# STC32G144K246 register map
Vendor: STC; File version: 2.0
Registers are 8-bit, read-write, no defined reset value unless marked. A register's access mark holds for its fields unless they carry their own. Offsets are from the block's base; [hi:lo] are bit positions; {n}, {i} and the like mark numbered series; 'fields as' and 'values as' point back to an identical list.

## PWMD — 高级 PWM D：使能、状态、计数、周期和输出
Base 0x007EF8B5
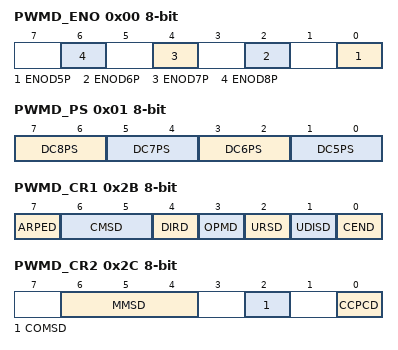
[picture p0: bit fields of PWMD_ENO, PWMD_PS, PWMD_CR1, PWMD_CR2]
0x00 PWMD_ENO — PWMD输出使能控制
  [2n-10] ENOD{n}P (n=5..8) — 尚未自动匹配到此字段的独立说明；请查看下方章节说明。
0x01 PWMD_PS — PWMD输出脚选择寄存器
  [7:6] DC8PS — 高级PWM 通道8 输出脚选择位
    0=P2.7; 1=P8.7; 2=P5.3; 3=PB.7
  [5:4] DC7PS — 高级PWMD 通道7 输出脚选择位
    0=P2.6; 1=P8.5; 2=P5.2; 3=PB.6
  [3:2] DC6PS — 高级PWMD 通道6 输出脚选择位
    0=P2.5; 1=P8.3; 2=P5.1; 3=PB.5
  [1:0] DC5PS — 高级PWMD 通道5 输出脚选择位
    0=P2.4; 1=P8.1; 2=P5.0; 3=PB.4
0x2B PWMD_CR1 — PWMD控制寄存器1
  [7] ARPED — 自动预装载允许位（n=A/B/C/D/E/F）
    0=PWMn_ARR 寄存器没有缓冲，它可以被直接写入; 1=PWMn_ARR 寄存器由预装载缓冲器缓冲
  [6:5] CMSD — 选择对齐模式（n=A/B/C/D/E/F）
    0=对齐模式：边沿对齐模式；说明：计数器依据方向位（DIR）向上或向下计数; 1=对齐模式：中央对齐模式1；说明：计数器交替地向上和向下计数。配置为输出的通道的输出比较中断标志位(CCnIF)只在计数器向下计数时被置1。; 2=对齐模式：中央对齐模式2；说明：计数器交替地向上和向下计数。配置为输出的通道的输出比较中断标志位(CCnIF)只在计数器向上计数时被置1。; 3=对齐模式：中央对齐模式3；说明：计数器交替地向上和向下计数。配置为输出的通道的输出比较中断标志位(CCnIF)在计数器向上和向下计数时均被置1。
  [4] DIRD — 计数器的计数方向（n=A/B/C/D/E/F）
    0=计数器向上计数；; 1=计数器向下计数。
  [3] OPMD — 单脉冲模式（n=A/B/C/D/E/F）
    0=在发生更新事件时，计数器不停止；; 1=在发生下一次更新事件时，清除CEN 位，计数器停止。
  [2] URSD — 更新请求源（n=A/B/C/D/E/F）
    0=如果UDIS 允许产生更新事件，则下述任一事件产生一个更新中断：; 1=如果UDIS 允许产生更新事件，则只有当下列事件发生时才产生更新中断，并UIF 置1：
  [1] UDISD — 禁止更新（n=A/B/C/D/E/F）
    0=一旦下列事件发生，产生更新（UEV）事件：; 1=不产生更新事件，影子寄存器（ARR、PSC、CCRx）保持它们的值。如果设置了UG 位或时钟/
  [0] CEND — 允许计数器（n=A/B/C/D/E/F）
    0=禁止计数器；; 1=使能计数器。
0x2C PWMD_CR2 — PWMD控制寄存器2
  [6:4] MMSD — 主模式选择（n=A/C/E）
    0=主模式：复位；说明：PWMn_EGR寄存器的UG位被用于作为触发输出（TRGO）。如果触发输入（时钟/触发控制器配置为复位模式）产生复位，则TRGO上的信号相对实际的复位会有一个延迟; 1=主模式：使能；说明：计数器使能信号被用于作为触发输出（TRGO）。其用于启动多个PWM，以便控制在一段时间内使能从PWM。计数器使能信号是通过CEN控制位和门控模式下的触发输入信号的逻辑或产生。除非选择了主/从模式，当计数器使能信号受控于触发输入时，TRGO上会有一个延迟。; 2=主模式：更新；说明：更新事件被选为触发输出（TRGO）; 3=主模式：比较脉冲；说明：一旦发生一次捕获或一次比较成功，当CCn5IF标志被置1时，触发输出送出一个正脉冲（TRGO）; {v}=主模式：比较；说明：OCn{v+1}REF信号被用于作为触发输出（TRGO） (v=4..7)
  [2] COMSD — 捕获/比较控制位的更新控制选择（n=A/B/C/D/E/F）
    0=当CCPCn=1 时，只有在COMG 位置1 的时候这些控制位才被更新; 1=当CCPCn=1 时，只有在COMG 位置1 或TRGI 发生上升沿的时候这些控制位才被更新
  [0] CCPCD — 捕获/比较预装载控制位（n=A/B/C/D/E/F）
    0=CCIE，CCINE，CCiP，CCiNP 和OCIM 位不是预装载的; 1=CCIE，CCINE，CCiP，CCiNP 和OCIM 位是预装载的；设置该位后，它们只在设置了COMG 位
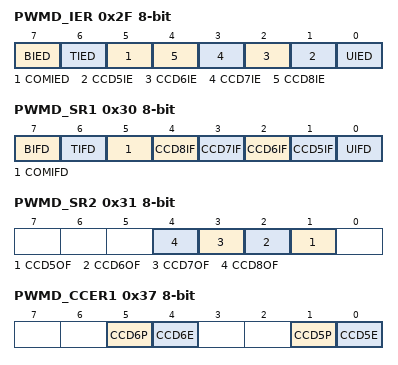
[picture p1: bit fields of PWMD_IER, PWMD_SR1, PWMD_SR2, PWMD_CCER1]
0x2F PWMD_IER — PWMD中断使能寄存器
  [7] BIED — 允许刹车中断（n=A/B/C/D/E/F）
    0=禁止刹车中断；; 1=允许刹车中断。
  [6] TIED — 触发中断使能（n=A/B/C/D/E/F）
    0=禁止触发中断；; 1=使能触发中断。
  [5] COMIED — 尚未自动匹配到此字段的独立说明；请查看下方章节说明。
  [n-4] CCD{n}IE (n=5..8) — 允许捕获/比较n 中断（n=A/B/C/D/E/F，x=1/2/3/4/5/6/7/8）
    0=禁止捕获/比较n 中断；; 1=允许捕获/比较n 中断。
  [0] UIED — 允许更新中断（n=A/B/C/D/E/F）
    0=禁止更新中断；; 1=允许更新中断。
0x30 PWMD_SR1 ro — PWMD状态寄存器1
  [7] BIFD — 刹车中断标记。一旦刹车输入有效，由硬件对该位置1。 如果刹车输入无效，则该位可由软件清0。（n=A/B/C/D/E/F）
    0=无刹车事件产生; 1=刹车输入上检测到有效电平
  [6] TIFD — 触发器中断标记。当发生触发事件时由硬件对该位置1。由软件清0。（n=A/B/C/D/E/F）
    0=无触发器事件产生; 1=触发中断等待响应
  [5] COMIFD — PWMn比较中断请求标志。需要软件清零。（n=A/B/C/D/E/F）
  [n-4] CCD{n}IF (n=5..8) — 捕获/比较nx中断标记，参考CC1IF描述（n=A/B/C/D/E/F，x=1/2/3/4/5/6/7/8）
  [0] UIFD — PWMn更新中断请求标志。需要软件清零。（n=A/B/C/D/E/F）
0x31 PWMD_SR2 ro — PWMD状态寄存器2
  [n-4] CCD{n}OF (n=5..8) — 捕获/比较nx重复捕获标记。参见CC1OF描述。（n=A/B/C/D/E/F，x=1/2/3/4/5/6/7/8）
0x37 PWMD_CCER1 — PWMD捕获比较使能寄存器1
  [5] CCD6P — OCn 输入捕获/比较输出极性。参考CCA1P（n=A/B/C/D/E/F，x=1/2/5/6）
  [4] CCD6E — OCn 输入捕获/比较输出使能。参考CCA1E（n=A/B/C/D/E/F，x=1/2/5/6）
  [1] CCD5P — OCn 输入捕获/比较输出极性。参考CCA1P（n=A/B/C/D/E/F，x=1/2/5/6）
  [0] CCD5E — OCn 输入捕获/比较输出使能。参考CCA1E（n=A/B/C/D/E/F，x=1/2/5/6）
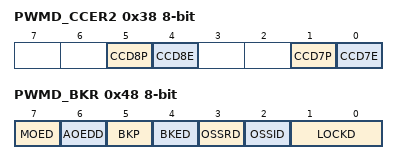
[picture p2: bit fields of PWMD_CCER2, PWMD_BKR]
0x38 PWMD_CCER2 — PWMD捕获比较使能寄存器2
  [5] CCD8P — OCn 输入捕获/比较输出极性。参考CCA1P（n=A/B/C/D/E/F，x=3/4/7/8）
  [4] CCD8E — OCn 输入捕获/比较输出使能。参考CCA1E（n=A/B/C/D/E/F，x=3/4/7/8）
  [1] CCD7P — OCn 输入捕获/比较输出极性。参考CCA1P（n=A/B/C/D/E/F，x=3/4/7/8）
  [0] CCD7E — OCn 输入捕获/比较输出使能。参考CCA1E（n=A/B/C/D/E/F，x=3/4/7/8）
0x39 PWMD_CNTRH ro — PWMD计数器高字节
  [7:0] CNTD — 计数器的16 位值（n=A/B/C/D/E/F）
0x3A PWMD_CNTRL ro — PWMD计数器低字节
  [7:0] CNTD — 计数器的16 位值（n=A/B/C/D/E/F）
0x3B PWMD_PSCRH — PWMD预分频高字节
  [7:0] PSCD — 预分频器的16 位值。（n=A/B/C/D/E/F） 预分频器用于对CK_PSC进行分频。计数器的时钟频率（fCK_CNT）等于fCK_PSC（/ PSCR[15:0]+1）。 PSCR 包含了当更新事件产生时装入当前预分频器寄存器的值（更新事件包括计数器被TIM_EGR 的UG 位清0 或被工作在
0x3C PWMD_PSCRL — PWMD预分频低字节
  fields as PWMD_PSCRH
0x3D PWMD_ARRH — PWMD自动重装寄存器高字节
  [7:0] ARRD — 自动重装载16 位值（n=A/B/C/D/E/F） ARR 包含了将要装载入实际的自动重装载寄存器的值。当自动重装载的值为0 时，计数器不工作。
0x3E PWMD_ARRL — PWMD自动重装寄存器低字节
  fields as PWMD_ARRH
0x40 PWMD_CCR5H — PWMD比较捕获寄存器5高位
  [7:0] CCRD5 — 捕获/比较n 的16 值（n=A/B/C/D/E/F，x=1/5） 若CCn 通道配置为输出：CCRn 包含了装入当前比较值（预装载值）。如果在PWMn_CCMR1 寄存 器（OCnPE 位）中未选择预装载功能，写入的数值会立即传输至当前寄存器中。否则只有当更新 事件发生时，此预装载值才传输至当前捕
0x41 PWMD_CCR5L — PWMD比较捕获寄存器5低位
  fields as PWMD_CCR5H
{0x36+2i} PWMD_CCR{i}H (i=6..8) — PWMD比较捕获寄存器{i}高位
  [7:0] CCRD{i} — 捕获/比较n 的16 位值（n=A/B/C/D/E/F，x={i-4}/{i}）
{0x37+2i} PWMD_CCR{i}L (i=6..8) — PWMD比较捕获寄存器{i}低位
  [7:0] CCRD{i} — 捕获/比较n 的16 位值（n=A/B/C/D/E/F，x={i-4}/{i}）
0x48 PWMD_BKR ro — PWMD刹车寄存器
  [7] MOED — 主输出使能。一旦刹车输入有效，该位被硬件异步清0。根据AOE 位的设置值，该位可以由软 件置1 或被自动置1。它仅对配置为输出的通道有效。（n=A/B/C/D/E/F）
    0=禁止OC 和OCN 输出或强制为空闲状态; 1=如果设置了相应的使能位（PWMn_CCERX 寄存器的CCIE 位），则使能OC 和OCN 输出。
  [6] AOEDD — 自动输出使能（n=A/B/C/D/E/F）
    0=MOE 只能被软件置1；; 1=MOE 能被软件置1 或在下一个更新事件被自动置1（如果刹车输入无效）。
  [5] BKP — 尚未自动匹配到此字段的独立说明；请查看下方章节说明。
  [4] BKED — 刹车功能使能（n=A/B/C/D/E/F）
    0=禁止刹车输入（BRK）; 1=开启刹车输入（BRK）
  [3] OSSRD — 运行模式下“关闭状态”选择。该位在MOE=1 且通道设为输出时有效（n=A/B/C/D/E/F）
    0=当PWM 不工作时，禁止OC/OCN 输出（OC/OCN 使能输出信号=0）；; 1=当 PWM 不工作时，一旦 CCiE=1 或 CCiNE=1，首先开启 OC/OCN 并输出无效电平，然后置
  [2] OSSID — 空闲模式下“关闭状态”选择。该位在MOE=0 且通道设为输出时有效。（n=A/B/C/D/E/F）
    0=当PWM 不工作时，禁止OC/OCN 输出（OC/OCN 使能输出信号=0）；; 1=当PWM 不工作时，一旦CCiE=1 或CCiNE=1，OC/OCN 首先输出其空闲电平，然后 OC/OCN
  [1:0] LOCKD — 锁定设置。该位为防止软件错误而提供的写保护措施（n=A/B/C/D/E/F）
    0=保护级别：无保护；保护内容：寄存器无写保护; 1=保护级别：锁定级别1；保护内容：不能写入PWMn_BKR寄存器的MOE、BKE、BKP、AOE位和PWMn_OISR寄存器的OISI位; 2=保护级别：锁定级别2；保护内容：不能写入锁定级别1中的各位，也不能写入CC极性位以及OSSR/OSSI位; 3=保护级别：锁定级别3；保护内容：不能写入锁定级别2中的各位，也不能写入CC控制位
